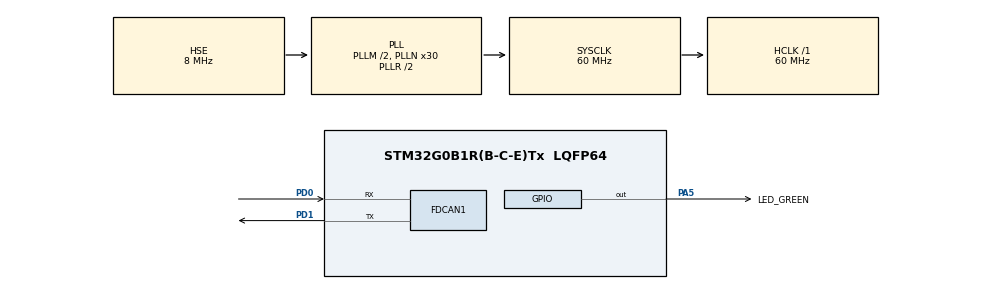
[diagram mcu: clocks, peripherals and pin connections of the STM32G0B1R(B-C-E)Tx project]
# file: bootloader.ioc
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FDCAN1.AutoRetransmission=ENABLE
FDCAN1.CalculateBaudRateNominal=416666
FDCAN1.CalculateTimeBitNominal=2400
FDCAN1.CalculateTimeQuantumNominal=800.0
FDCAN1.FrameFormat=FDCAN_FRAME_FD_BRS
FDCAN1.ProtocolException=ENABLE
Mcu.Family=STM32G0
Mcu.Name=STM32G0B1R(B-C-E)Tx
Mcu.Package=LQFP64
NVIC.TIM16_FDCAN_IT0_IRQn=true\:0\:0\:false\:false\:true\:true\:true\:true
PA13.GPIO_Label=TMS
PA13.Mode=Serial_Wire
PA13.Signal=SYS_SWDIO
PA14-BOOT0.GPIO_Label=TCK
PA14-BOOT0.Mode=Serial_Wire
PA14-BOOT0.Signal=SYS_SWCLK
PA5.GPIO_Label=LED_GREEN
PA5.GPIO_Speed=GPIO_SPEED_FREQ_HIGH
PA5.Signal=GPIO_Output
PC14-OSC32_IN\ (PC14).Mode=LSE-External-Oscillator
PC14-OSC32_IN\ (PC14).Signal=RCC_OSC32_IN
PC15-OSC32_OUT\ (PC15).Mode=LSE-External-Oscillator
PC15-OSC32_OUT\ (PC15).Signal=RCC_OSC32_OUT
PD0.Mode=FDCAN_Activate
PD0.Signal=FDCAN1_RX
PD1.Mode=FDCAN_Activate
PD1.Signal=FDCAN1_TX
PF0-OSC_IN\ (PF0).GPIO_Label=MCO
PF0-OSC_IN\ (PF0).Mode=HSE-External-Oscillator
PF0-OSC_IN\ (PF0).Signal=RCC_OSC_IN
PF1-OSC_OUT\ (PF1).Mode=HSE-External-Oscillator
PF1-OSC_OUT\ (PF1).Signal=RCC_OSC_OUT
ProjectManager.HeapSize=0x200
ProjectManager.StackSize=0x400
ProjectManager.TargetToolchain=STM32CubeIDE
RCC.ADCFreq_Value=60000000
RCC.AHBFreq_Value=60000000
RCC.CortexFreq_Value=60000000
RCC.EXTERNAL_CLOCK_VALUE=12288000
RCC.FDCANCLockSelection=RCC_FDCANCLKSOURCE_PLL
RCC.HCLKFreq_Value=60000000
RCC.HSI48_VALUE=48000000
RCC.HSI_VALUE=16000000
RCC.PLLM=RCC_PLLM_DIV2
RCC.PLLN=30
RCC.PLLQ=RCC_PLLQ_DIV6
RCC.PLLSourceVirtual=RCC_PLLSOURCE_HSE
RCC.SYSCLKFreq_VALUE=60000000
RCC.SYSCLKSource=RCC_SYSCLKSOURCE_PLLCLK
RCC.USBFreq_Value=48000000
RCC.VCOOutputFreq_Value=120000000
VP_CRC_VS_CRC.Mode=CRC_Activate
VP_SYS_VS_DBSignals.Mode=DisableDeadBatterySignals
board=NUCLEO-G0B1RE

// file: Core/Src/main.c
/* USER CODE BEGIN Header */
/**
  ******************************************************************************
  * @file           : main.c
  * @brief          : Main program body
  ******************************************************************************
  * @attention
  *
  * Copyright (c) 2025 STMicroelectronics.
  * All rights reserved.
  *
  * This software is licensed under terms that can be found in the LICENSE file
  * in the root directory of this software component.
  * If no LICENSE file comes with this software, it is provided AS-IS.
  *
  ******************************************************************************
  */
/* USER CODE END Header */
#include "main.h"

/* USER CODE BEGIN Includes */
#include "flash_utils.h"    // suas funções de flash
#include "string.h"         // para memcpy, memset, etc.
/* USER CODE END Includes */

/* USER CODE BEGIN PTD */

#define ECU_ID  0x01  // MUDAR PARA CADA ECU 0x01 0x02...

FDCAN_RxHeaderTypeDef RxHeader;
uint8_t RxData[8];

uint32_t crc_recebido = 0;
uint32_t firmware_tamanho = 0;

bool start_recebido = false;

void jump_to_application(void)
{
    uint32_t appAddress = 0x08004000;
    uint32_t appStack = *(volatile uint32_t*)appAddress;
    uint32_t appResetHandler = *(volatile uint32_t*)(appAddress + 4);

    void (*appMain)(void) = (void*)appResetHandler;

    __disable_irq();
    __set_MSP(appStack);
    appMain();
}
/* USER CODE END PTD */

CRC_HandleTypeDef hcrc;

FDCAN_HandleTypeDef hfdcan1;

void SystemClock_Config(void);
static void MX_GPIO_Init(void);
static void MX_FDCAN1_Init(void);
static void MX_CRC_Init(void);

int main(void)
{

  /* MCU Configuration--------------------------------------------------------*/

  /* Reset of all peripherals, Initializes the Flash interface and the Systick. */
  HAL_Init();

  /* Configure the system clock */
  SystemClock_Config();

  /* Initialize all configured peripherals */
  MX_GPIO_Init();
  MX_FDCAN1_Init();
  MX_CRC_Init();
  /* USER CODE BEGIN 2 */

  HAL_FDCAN_Start(&hfdcan1); //inicia fdcan
  HAL_FDCAN_ActivateNotification(&hfdcan1, FDCAN_IT_RX_FIFO0_NEW_MESSAGE, 0); //ativa interruptor a cada msg

  // aguarda 0.5 segundo por uma possível atualização
  uint32_t start_timeout = HAL_GetTick();
  while (HAL_GetTick() - start_timeout < 500) {

      // Se o START for recebido, a flag start_recebido será setada via callback

  }

  // Se não recebeu comando de START, pula para aplicação normal
  if (!start_recebido) {
      jump_to_application();
  }

  /* USER CODE END 2 */

  /* Infinite loop */
  while (1)
  {

  }
}

void SystemClock_Config(void)
{
  RCC_OscInitTypeDef RCC_OscInitStruct = {0};
  RCC_ClkInitTypeDef RCC_ClkInitStruct = {0};

  /** Configure the main internal regulator output voltage
  */
  HAL_PWREx_ControlVoltageScaling(PWR_REGULATOR_VOLTAGE_SCALE1);

  /** Initializes the RCC Oscillators according to the specified parameters
  * in the RCC_OscInitTypeDef structure.
  */
  RCC_OscInitStruct.OscillatorType = RCC_OSCILLATORTYPE_HSE;
  RCC_OscInitStruct.HSEState = RCC_HSE_ON;
  RCC_OscInitStruct.PLL.PLLState = RCC_PLL_ON;
  RCC_OscInitStruct.PLL.PLLSource = RCC_PLLSOURCE_HSE;
  RCC_OscInitStruct.PLL.PLLM = RCC_PLLM_DIV2;
  RCC_OscInitStruct.PLL.PLLN = 30;
  RCC_OscInitStruct.PLL.PLLP = RCC_PLLP_DIV2;
  RCC_OscInitStruct.PLL.PLLQ = RCC_PLLQ_DIV6;
  RCC_OscInitStruct.PLL.PLLR = RCC_PLLR_DIV2;
  if (HAL_RCC_OscConfig(&RCC_OscInitStruct) != HAL_OK)
  {
    Error_Handler();
  }

  /** Initializes the CPU, AHB and APB buses clocks
  */
  RCC_ClkInitStruct.ClockType = RCC_CLOCKTYPE_HCLK|RCC_CLOCKTYPE_SYSCLK
                              |RCC_CLOCKTYPE_PCLK1;
  RCC_ClkInitStruct.SYSCLKSource = RCC_SYSCLKSOURCE_PLLCLK;
  RCC_ClkInitStruct.AHBCLKDivider = RCC_SYSCLK_DIV1;
  RCC_ClkInitStruct.APB1CLKDivider = RCC_HCLK_DIV1;

  if (HAL_RCC_ClockConfig(&RCC_ClkInitStruct, FLASH_LATENCY_2) != HAL_OK)
  {
    Error_Handler();
  }
}

static void MX_CRC_Init(void)
{

  hcrc.Instance = CRC;
  hcrc.Init.DefaultPolynomialUse = DEFAULT_POLYNOMIAL_ENABLE;
  hcrc.Init.DefaultInitValueUse = DEFAULT_INIT_VALUE_ENABLE;
  hcrc.Init.InputDataInversionMode = CRC_INPUTDATA_INVERSION_NONE;
  hcrc.Init.OutputDataInversionMode = CRC_OUTPUTDATA_INVERSION_DISABLE;
  hcrc.InputDataFormat = CRC_INPUTDATA_FORMAT_BYTES;
  if (HAL_CRC_Init(&hcrc) != HAL_OK)
  {
    Error_Handler();
  }

}

static void MX_FDCAN1_Init(void)
{

  hfdcan1.Instance = FDCAN1;
  hfdcan1.Init.ClockDivider = FDCAN_CLOCK_DIV1;
  hfdcan1.Init.FrameFormat = FDCAN_FRAME_FD_BRS;
  hfdcan1.Init.Mode = FDCAN_MODE_NORMAL;
  hfdcan1.Init.AutoRetransmission = ENABLE;
  hfdcan1.Init.TransmitPause = DISABLE;
  hfdcan1.Init.ProtocolException = ENABLE;
  hfdcan1.Init.NominalPrescaler = 4;
  hfdcan1.Init.NominalSyncJumpWidth = 1;
  hfdcan1.Init.NominalTimeSeg1 = 13;
  hfdcan1.Init.NominalTimeSeg2 = 2;
  hfdcan1.Init.DataPrescaler = 1;
  hfdcan1.Init.DataSyncJumpWidth = 2;
  hfdcan1.Init.DataTimeSeg1 = 13;
  hfdcan1.Init.DataTimeSeg2 = 2;
  hfdcan1.Init.StdFiltersNbr = 0;
  hfdcan1.Init.ExtFiltersNbr = 0;
  hfdcan1.Init.TxFifoQueueMode = FDCAN_TX_FIFO_OPERATION;
  if (HAL_FDCAN_Init(&hfdcan1) != HAL_OK)
  {
    Error_Handler();
  }

}

static void MX_GPIO_Init(void)
{
  GPIO_InitTypeDef GPIO_InitStruct = {0};

  /* GPIO Ports Clock Enable */
  __HAL_RCC_GPIOC_CLK_ENABLE();
  __HAL_RCC_GPIOF_CLK_ENABLE();
  __HAL_RCC_GPIOA_CLK_ENABLE();
  __HAL_RCC_GPIOD_CLK_ENABLE();

  /*Configure GPIO pin Output Level */
  HAL_GPIO_WritePin(LED_GREEN_GPIO_Port, LED_GREEN_Pin, GPIO_PIN_RESET);

  /*Configure GPIO pin : LED_GREEN_Pin */
  GPIO_InitStruct.Pin = LED_GREEN_Pin;
  GPIO_InitStruct.Mode = GPIO_MODE_OUTPUT_PP;
  GPIO_InitStruct.Pull = GPIO_NOPULL;
  GPIO_InitStruct.Speed = GPIO_SPEED_FREQ_HIGH;
  HAL_GPIO_Init(LED_GREEN_GPIO_Port, &GPIO_InitStruct);

}

/* USER CODE BEGIN 4 */
void HAL_FDCAN_RxFifo0Callback(FDCAN_HandleTypeDef *hfdcan, uint32_t RxFifo0ITs)
{

    if ((RxFifo0ITs & FDCAN_IT_RX_FIFO0_NEW_MESSAGE) == 0)
    	return;

	HAL_FDCAN_GetRxMessage(hfdcan, FDCAN_RX_FIFO0, &RxHeader, RxData);

	uint8_t destino = RxData[0];

		if (destino != ECU_ID)
			return;  // Ignora esse comando: ele é para outra ECU

	// Verifica se há dados suficientes para um CRC

	if (RxHeader.Identifier == 0x002 && RxHeader.DataLength >= FDCAN_DLC_BYTES_8) {
		uint8_t tamanho_util = 7;  // ECU_ID (1) + endereco (4) + dados (2~3)
		uint8_t crc_recebido = RxData[7];
		uint8_t crc_calculado = calcular_crc8(RxData, 7);  // não inclui o byte CRC

		if (crc_calculado != crc_recebido) {
			// CRC inválido — descarta pacote
			return;
		}
	}

	switch (RxHeader.Identifier)
	{

	case 0x000:  // START
		start_recebido = true;
		break;

		case 0x001:  // ERASE
			apagar_flash_aplicacao();
			firmware_tamanho = 0;
			break;

		case 0x002:  // WRITE
					{
						uint32_t endereco = *(uint32_t*)&RxData[1];  // Skip ECU_ID
						if (endereco >= 0x08004000 && endereco < 0x08040000)
						{
							gravar_bloco_na_flash(endereco, &RxData[5], 2);  // apenas os 2 bytes de dados reais
							firmware_tamanho += 8;

							// Enviar ACK
							uint8_t ack_data[4];
							memcpy(ack_data, &endereco, 4);

							FDCAN_TxHeaderTypeDef txHeader;
							txHeader.Identifier = 0x005;
							txHeader.IdType = FDCAN_STANDARD_ID;
							txHeader.TxFrameType = FDCAN_DATA_FRAME;
							txHeader.DataLength = FDCAN_DLC_BYTES_4;
							txHeader.ErrorStateIndicator = FDCAN_ESI_ACTIVE;
							txHeader.BitRateSwitch = FDCAN_BRS_OFF;
							txHeader.FDFormat = FDCAN_CLASSIC_CAN;
							txHeader.TxEventFifoControl = FDCAN_NO_TX_EVENTS;
							txHeader.MessageMarker = 0;

							HAL_FDCAN_AddMessageToTxFifoQ(&hfdcan1, &txHeader, ack_data);
						}
						break;
					}

		case 0x003:  // END
		{
			uint32_t crc_calculado = calcular_crc_da_aplicacao(0x08004000, firmware_tamanho);
			if (crc_calculado == crc_recebido)
			{
				jump_to_application();
			}
			else
			{
				NVIC_SystemReset();
			}
			break;
		}

		case 0x004:  // CRC + TAMANHO
		{
			crc_recebido = *(uint32_t*)&RxData[1];
			firmware_tamanho = *(uint32_t*)&RxData[5];
			break;
		}

		default:
			break;
	}

}

/* USER CODE END 4 */

void Error_Handler(void)
{
  __disable_irq();
  while (1)
  {
  }
}
